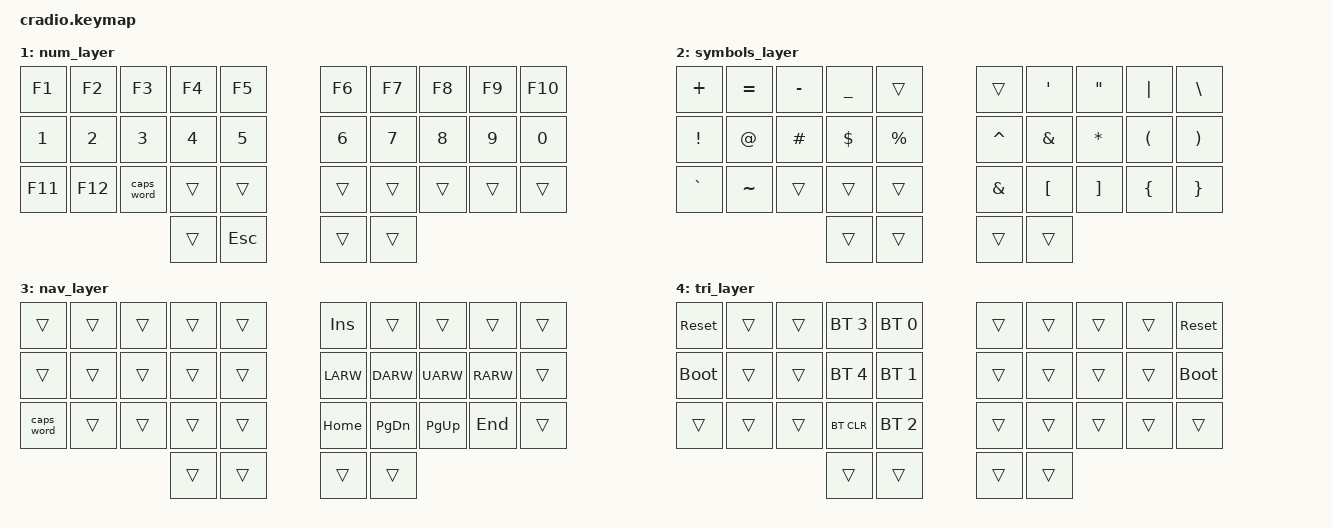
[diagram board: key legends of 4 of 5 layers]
// Copyright (c) 2022 The ZMK Contributors
// SPDX-License-Identifier: MIT

#include <behaviors.dtsi>
#include <dt-bindings/zmk/keys.h>
#include <dt-bindings/zmk/bt.h>

// Home row mods macro
#define HRML(k1,k2,k3,k4) &ht LSHFT k1  &ht LCTRL k2  &ht LGUI k3  &ht LALT k4
#define HRMR(k1,k2,k3,k4) &ht RALT k1  &ht RGUI k2  &ht RCTRL k3  &ht RSHFT k4

// combo macro
#define COMBO(name, pos, bind) name { timeout-ms = <20>; key-positions = pos ; bindings = bind ; };

/ {
    behaviors {
        ht: hold_tap {
            label = "hold_tap";
            compatible = "zmk,behavior-hold-tap";
            #binding-cells = <2>;
            flavor = "balanced";
            tapping-term-ms = <220>;
            quick-tap-ms = <150>;
            #global-quick-tap;
            bindings = <&kp>, <&kp>;
        };
    };

    conditional_layers {
        compatible = "zmk,conditional-layers";
        tri_layer {
            if-layers = <1 2>;
            then-layer = <4>;
        };
    };

    combos {
        compatible = "zmk,combos";
        combo_esc {
            timeout-ms = <50>;
            key-positions = <30 31>;
            bindings = <&kp ESC>;
        };

        COMBO(combo_caps,  <10 19>, <&caps_word>)

        COMBO(combo_del,   <32 33>, <&kp DEL>)
        COMBO(combo_lpar,  <12 13>, <&kp LPAR>)
        COMBO(combo_rpar,  <16 17>, <&kp RPAR>)
        COMBO(combo_lbkt,  <2  3 >, <&kp LBKT>)
        COMBO(combo_rbkt,  <6  7 >, <&kp RBKT>)
        COMBO(combo_lbrc,  <11 12>, <&kp LBRC>)
        COMBO(combo_rbrc,  <17 18>, <&kp RBRC>)
        COMBO(combo_lt,    <1  2 >, <&kp LT>)
        COMBO(combo_gt,    <7  8 >, <&kp GT>)
    };

    keymap {
        compatible = "zmk,keymap";
        default_layer {
            bindings = <
        //╭──────────┬──────────┬──────────┬──────────┬──────────╮   ╭──────────┬──────────┬──────────┬──────────┬──────────╮
        //│  Q       │  W       │  E       │  R       │  T       │   │  Y       │  U       │  I       │  O       │  P       │
            &kp Q      &kp W      &kp E      &kp R      &kp T          &kp Y      &kp U      &kp I      &kp O      &kp P
        //├──────────┼──────────┼──────────┼──────────┼──────────┤   ├──────────┼──────────┼──────────┼──────────┼──────────┤
        //│  A       │  S       │  D       │  F       │  G       │   │  H       │  J       │  K       │  L       │  : ;     │
            HRML(A,        S,         D,         F)     &kp G          &kp H      HRMR(J,        K,         L,      SEMI)
        //├──────────┼──────────┼──────────┼──────────┼──────────┤   ├──────────┼──────────┼──────────┼──────────┼──────────┤
        //│  Z       │  X       │  C       │  V       │  B       │   │  N       │  M       │ , <      │ . >      │ / ?      │
            &kp Z      &kp X      &kp C      &kp V      &kp B          &kp N      &kp M      &kp COMMA  &kp DOT    &kp FSLH
        //╰──────────┴──────────┴──────────┼──────────┼──────────┤   ├──────────┼──────────┼──────────┴──────────┴──────────╯
                                           &lt 3 ENTER &lt 2 SPACE     &lt 1 BSPC  &kp TAB
        //                                 ╰──────────┴──────────╯   ╰──────────┴──────────╯
            >;
        };

        num_layer {
            bindings = <
        //╭──────────┬──────────┬──────────┬──────────┬──────────╮   ╭──────────┬──────────┬──────────┬──────────┬──────────╮
        //│ F1       │  F2      │  F3      │  F4      │ F5       │   │ F6       │ F7       │ F8       │ F9       │  F10     │
            &kp F1     &kp F2     &kp F3     &kp F4     &kp F5         &kp F6     &kp F7     &kp F8     &kp F9      &kp F10
        //├──────────┼──────────┼──────────┼──────────┼──────────┤   ├──────────┼──────────┼──────────┼──────────┼──────────┤
        //│ 1        │  2       │  3       │  4       │ 5        │   │ 6        │ 7        │ 8        │ 9        │  0       │
            &kp N1      &kp N2     &kp N3     &kp N4     &kp N5        &kp N6     &kp N7     &kp N8     &kp N9      &kp N0
        //├──────────┼──────────┼──────────┼──────────┼──────────┤   ├──────────┼──────────┼──────────┼──────────┼──────────┤
        //│ F11      │  F12     │  caps    │          │          │   │          │          │          │          │          │
           &kp F11    &kp F12    &caps_word  &trans     &trans         &trans     &trans     &trans     &trans     &trans
        //╰──────────┴──────────┴──────────┼──────────┼──────────┤   ├──────────┼──────────┼──────────┴──────────┴──────────╯
                                             &trans     &kp ESC        &trans     &trans
        //                                 ╰──────────┴──────────╯   ╰──────────┴──────────╯
            >;
        };


         symbols_layer {
            bindings = <
        //╭──────────┬──────────┬──────────┬──────────┬──────────╮   ╭──────────┬──────────┬──────────┬──────────┬──────────╮
        //│ +        │  =       │  -       │  _       │          │   │          │  '       │  "       │  |       │  \       │
            &kp PLUS   &kp EQUAL  &kp MINUS  &kp UNDER  &trans         &trans     &kp SQT    &kp DQT    &kp PIPE   &kp BSLH
        //├──────────┼──────────┼──────────┼──────────┼──────────┤   ├──────────┼──────────┼──────────┼──────────┼──────────┤
        //│  !       │  @       │  #       │  $       │  %       │   │  ^       │  &       │  *       │  (       │  )       │
            &kp EXCL   &kp AT     &kp HASH   &kp DLLR   &kp PRCNT      &kp CARET  &kp AMPS  &kp ASTRK  &kp LPAR   &kp RPAR
        //├──────────┼──────────┼──────────┼──────────┼──────────┤   ├──────────┼──────────┼──────────┼──────────┼──────────┤
        //│ `        │ ~        │          │          │          │   │          │  [       │  ]       │  {       │ }        │
            &kp GRAVE  &kp TILDE  &trans     &trans     &trans         &kp AMPS   &kp LBKT  &kp RBKT   &kp LBRC   &kp RBRC
        //╰──────────┴──────────┴──────────┼──────────┼──────────┤   ├──────────┼──────────┼──────────┴──────────┴──────────╯
                                             &trans     &trans         &trans     &trans
        //                                 ╰──────────┴──────────╯   ╰──────────┴──────────╯
            >;
        };

        nav_layer {
            bindings = <
        //╭──────────┬──────────┬──────────┬──────────┬──────────╮   ╭──────────┬──────────┬──────────┬──────────┬──────────╮
        //│          │          │          │          │          │   │          │          │          │          │          │
            &trans     &trans     &trans     &trans     &trans         &kp INS    &trans     &trans     &trans     &trans
        //├──────────┼──────────┼──────────┼──────────┼──────────┤   ├──────────┼──────────┼──────────┼──────────┼──────────┤
        //│          │          │          │          │          │   │ up       │ down     │ up       │ right    │          │
            &trans      &trans     &trans     &trans     &trans        &kp LARW   &kp DARW   &kp UARW   &kp RARW   &trans
        //├──────────┼──────────┼──────────┼──────────┼──────────┤   ├──────────┼──────────┼──────────┼──────────┼──────────┤
        //│ CAPS     │          │          │          │          │   │          │          │          │          │          │
           &caps_word  &trans     &trans     &trans     &trans         &kp HOME   &kp PG_DN  &kp PG_UP  &kp END    &trans
        //╰──────────┴──────────┴──────────┼──────────┼──────────┤   ├──────────┼──────────┼──────────┴──────────┴──────────╯
                                             &trans     &trans         &trans     &trans
        //                                 ╰──────────┴──────────╯   ╰──────────┴──────────╯
            >;
        };



        tri_layer {
            bindings = <
        //╭──────────┬──────────┬──────────┬──────────┬──────────╮   ╭──────────┬──────────┬──────────┬──────────┬──────────╮
        //│ RESET    │          │          │          │PROFILE 0 │   │          │          │          │          │  RESET   │
           &sys_reset  &trans     &trans  &bt BT_SEL 3 &bt BT_SEL 0    &trans     &trans     &trans     &trans    &sys_reset
        //├──────────┼──────────┼──────────┼──────────┼──────────┤   ├──────────┼──────────┼──────────┼──────────┼──────────┤
        //│BOOTLOADER│          │          │          │PROFILE 1 │   │          │          │          │          │BOOTLOADER│
          &bootloader  &trans     &trans  &bt BT_SEL 4 &bt BT_SEL 1    &trans     &trans     &trans     &trans    &bootloader
        //├──────────┼──────────┼──────────┼──────────┼──────────┤   ├──────────┼──────────┼──────────┼──────────┼──────────┤
        //│          │          │          │ CLEAR BT │PROFILE 2 │   │          │          │          │          │          │
            &trans     &trans     &trans    &bt BT_CLR &bt BT_SEL 2    &trans     &trans     &trans     &trans     &trans
        //╰──────────┴──────────┴──────────┼──────────┼──────────┤   ├──────────┼──────────┼──────────┴──────────┴──────────╯
                                             &trans     &trans         &trans     &trans
        //                                 ╰──────────┴──────────╯   ╰──────────┴──────────╯
            >;
        };
    };
};
